# f28p551x_analog_subsys_regs register map
Vendor: Texas Instruments
Peripheral module from a debugger description file (folder C2000).
Address unit: 16 bits
Registers are 32-bit, read-write, no defined reset value unless marked. A register's access mark holds for its fields unless they carry their own. Offsets are as the file gives them; lines under a group give offsets from that group; [hi:lo] are bit positions; {n}, {i} and the like mark numbered series; 'fields as' and 'values as' point back to an identical list; <NAME> marks a mode.

## ANALOG_SUBSYS_REGS — ANALOG SUBSYS Registers
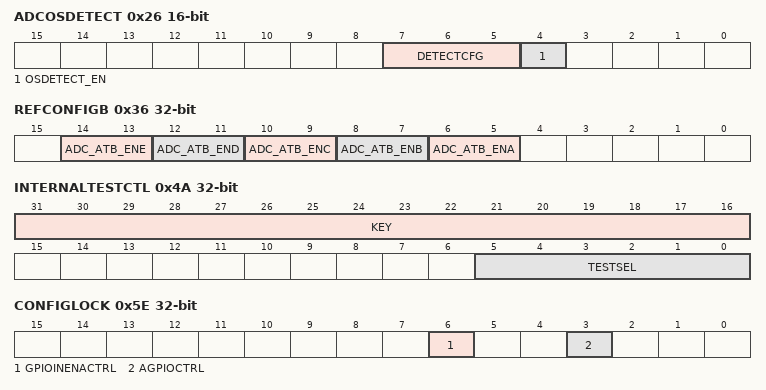
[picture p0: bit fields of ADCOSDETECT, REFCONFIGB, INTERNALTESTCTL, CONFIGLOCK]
0x26 ADCOSDETECT 16-bit — I2V Logic Control
  [7:5] DETECTCFG — OS detect config bits
  [4] OSDETECT_EN — Enable OS Detect Logic
0x36 REFCONFIGB — Config register for analog reference B.
  [14:13] ADC_ATB_ENE — ADC E testmux enable
  [12:11] ADC_ATB_END — ADC D testmux enable
  [10:9] ADC_ATB_ENC — ADC C testmux enable
  [8:7] ADC_ATB_ENB — ADC B testmux enable
  [6:5] ADC_ATB_ENA — ADC A testmux enable
0x4A INTERNALTESTCTL — INTERNALTEST Node Control Register
  [31:16] KEY — Key to Enable writes
  [5:0] TESTSEL — Test Select
0x5E CONFIGLOCK — Lock Register for all the config registers.
  [6] GPIOINENACTRL — Locks all GPIOINENACTRL Register
  [3] AGPIOCTRL — Locks all AGPIOCTRL Register
0x60 TSNSCTL 16-bit — Temperature Sensor Control Register
  [0] ENABLE — Temperature Sensor Enable
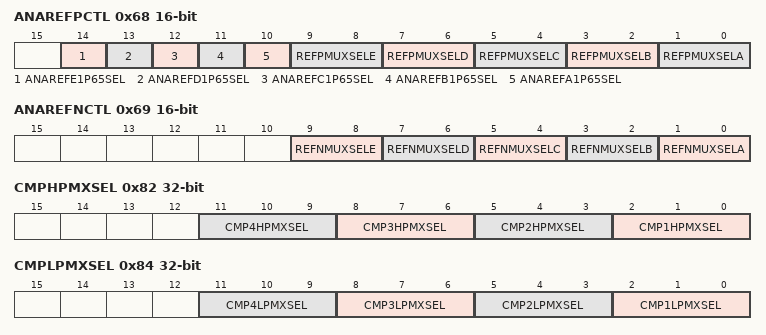
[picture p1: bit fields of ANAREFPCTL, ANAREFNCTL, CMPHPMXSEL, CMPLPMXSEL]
0x68 ANAREFPCTL 16-bit — Analog Reference Control Register for VREFHI
  [14] ANAREFE1P65SEL — 1.65v Reference Select ADCE
  [13] ANAREFD1P65SEL — 1.65v Reference Select ADCD
  [12] ANAREFC1P65SEL — 1.65v Reference Select ADCC
  [11] ANAREFB1P65SEL — 1.65v Reference Select ADCB
  [10] ANAREFA1P65SEL — 1.65v Reference Select ADCA
  [9:8] REFPMUXSELE — Analog Reference Select ADCE
  [7:6] REFPMUXSELD — Analog Reference Select ADCD
  [5:4] REFPMUXSELC — Analog Reference Select ADCC
  [3:2] REFPMUXSELB — Analog Reference Select ADCB
  [1:0] REFPMUXSELA — Analog Reference Select ADCA
0x69 ANAREFNCTL 16-bit — Analog Reference Control Register for VREFLO
  [9:8] REFNMUXSELE — Analog Reference Select ADCE
  [7:6] REFNMUXSELD — Analog Reference Select ADCD
  [5:4] REFNMUXSELC — Analog Reference Select ADCC
  [3:2] REFNMUXSELB — Analog Reference Select ADCB
  [1:0] REFNMUXSELA — Analog Reference Select ADCA
0x70 VMONCTL 16-bit — Voltage Monitor Control Register
  [8] BORLVMONDIS — Disable BORL(ow) feature on VDDIO
0x82 CMPHPMXSEL — Bits to select one of the many sources on CompHP inputs. Refer to Pimux diagram for details.
  [3n-1:3n-3] CMP{n}HPMXSEL (n=1..4) — CMP{n}HPMXSEL bits
0x84 CMPLPMXSEL — Bits to select one of the many sources on CompLP inputs. Refer to Pimux diagram for details.
  [3n-1:3n-3] CMP{n}LPMXSEL (n=1..4) — CMP{n}LPMXSEL bits
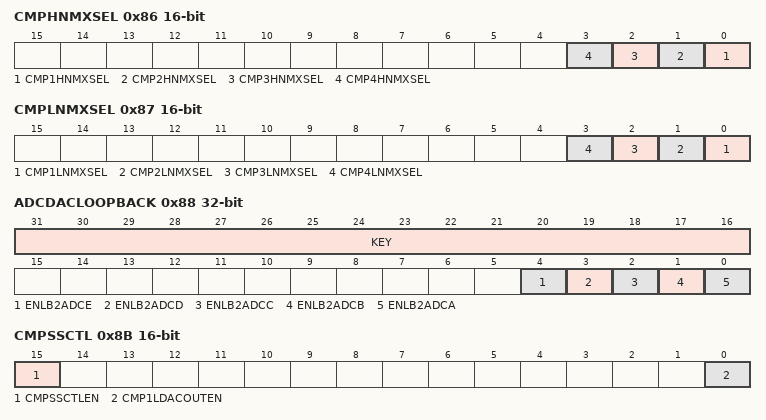
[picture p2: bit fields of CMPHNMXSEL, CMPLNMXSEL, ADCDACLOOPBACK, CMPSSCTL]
0x86 CMPHNMXSEL 16-bit — Bits to select one of the many sources on CompHN inputs. Refer to Pimux diagram for details.
  [n-1] CMP{n}HNMXSEL (n=1..4) — CMP{n}HNMXSEL bits
0x87 CMPLNMXSEL 16-bit — Bits to select one of the many sources on CompLN inputs. Refer to Pimux diagram for details.
  [n-1] CMP{n}LNMXSEL (n=1..4) — CMP{n}LNMXSEL bits
0x88 ADCDACLOOPBACK — Enabble loopback from DAC to ADCs
  [31:16] KEY — Key to enable writes
  [4] ENLB2ADCE — Enable DACA loopback to ADCE
  [3] ENLB2ADCD — Enable DACA loopback to ADCD
  [2] ENLB2ADCC — Enable DACA loopback to ADCC
  [1] ENLB2ADCB — Enable DACA loopback to ADCB
  [0] ENLB2ADCA — Enable DACA loopback to ADCA
0x8B CMPSSCTL 16-bit — CMPSS Control Register
  [15] CMPSSCTLEN — Enable the CMPSSCTL Register
  [0] CMP1LDACOUTEN — Enable general purpose DAC functionality for CMPSS1.COMPDACL
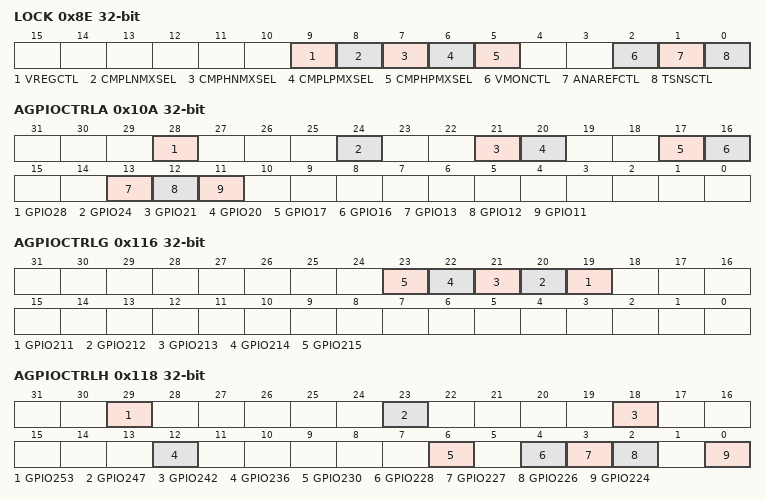
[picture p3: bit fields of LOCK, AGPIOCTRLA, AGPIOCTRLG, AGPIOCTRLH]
0x8E LOCK
  [9] VREGCTL — VREGCTL Register lock bit
  [8] CMPLNMXSEL — CMPLNMXSEL Register lock bit
  [7] CMPHNMXSEL — CMPHNMXSEL Register lock bit
  [6] CMPLPMXSEL — CMPLPMXSEL Register lock bit
  [5] CMPHPMXSEL — CMPHPMXSEL Register lock bit
  [2] VMONCTL — VMONCTL Register lock bit
  [1] ANAREFCTL — ANAREFCTL Register lock bit
  [0] TSNSCTL — TSNSCTL Register lock bit
0x10A AGPIOCTRLA — AGPIO Control Register
  [28] GPIO28 — AGPIOCTRL for GPIO28
  [24] GPIO24 — AGPIOCTRL for GPIO24
  [21] GPIO21 — AGPIOCTRL for GPIO21
  [20] GPIO20 — AGPIOCTRL for GPIO20
  [17] GPIO17 — AGPIOCTRL for GPIO17
  [16] GPIO16 — AGPIOCTRL for GPIO16
  [13] GPIO13 — AGPIOCTRL for GPIO13
  [12] GPIO12 — AGPIOCTRL for GPIO12
  [11] GPIO11 — AGPIOCTRL for GPIO11
0x10C AGPIOCTRLB — AGPIO Control Register
  [1] GPIO33 — AGPIOCTRL for GPIO33
0x116 AGPIOCTRLG — AGPIO Control Register
  [n-192] GPIO{n} (n=211..215) — AGPIOCTRL for GPIO{n}
0x118 AGPIOCTRLH — AGPIO Control Register
  [29] GPIO253 — AGPIOCTRL for GPIO253
  [23] GPIO247 — AGPIOCTRL for GPIO247
  [18] GPIO242 — AGPIOCTRL for GPIO242
  [12] GPIO236 — AGPIOCTRL for GPIO236
  [6] GPIO230 — AGPIOCTRL for GPIO230
  [4] GPIO228 — AGPIOCTRL for GPIO228
  [3] GPIO227 — AGPIOCTRL for GPIO227
  [2] GPIO226 — AGPIOCTRL for GPIO226
  [0] GPIO224 — AGPIOCTRL for GPIO224
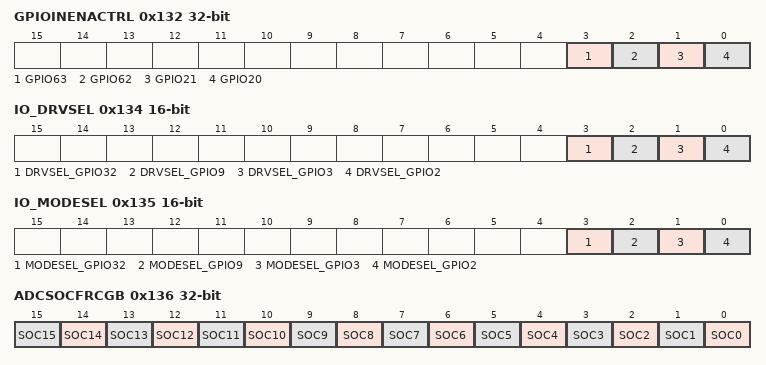
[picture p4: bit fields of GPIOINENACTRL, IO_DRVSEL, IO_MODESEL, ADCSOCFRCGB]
0x132 GPIOINENACTRL — GPIOINENACTRL Control Register
  [3] GPIO63 — Input Buffer Control for GPIO63
  [2] GPIO62 — Input Buffer Control for GPIO62
  [1] GPIO21 — Input Buffer Control for GPIO21
  [0] GPIO20 — Input Buffer Control for GPIO20
0x134 IO_DRVSEL 16-bit — IO Drive strength select register
  [3] DRVSEL_GPIO32 — Drive select for GPIO 32
  [2] DRVSEL_GPIO9 — Drive select for GPIO 9
  [1] DRVSEL_GPIO3 — Drive select for GPIO 3
  [0] DRVSEL_GPIO2 — Drive select for GPIO 2
0x135 IO_MODESEL 16-bit — IO Mode select register
  [3] MODESEL_GPIO32 — Mode select for GPIO 32
  [2] MODESEL_GPIO9 — Mode select for GPIO 9
  [1] MODESEL_GPIO3 — Mode select for GPIO 3
  [0] MODESEL_GPIO2 — Mode select for GPIO 2
0x136 ADCSOCFRCGB — ADC Global SOC Force
  [n] SOC{n} (n=0..15) — Generate synchronous SW trigger for SOC{n}
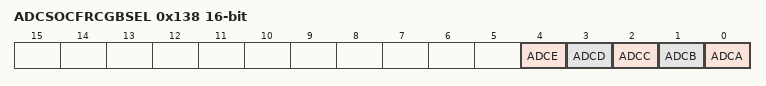
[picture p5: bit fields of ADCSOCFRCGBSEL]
0x138 ADCSOCFRCGBSEL 16-bit — ADC Global SOC Force Select
  [4] ADCE — Generate synchronous SW trigger for ADCE
  [3] ADCD — Generate synchronous SW trigger for ADCD
  [2] ADCC — Generate synchronous SW trigger for ADCC
  [1] ADCB — Generate synchronous SW trigger for ADCB
  [0] ADCA — Generate synchronous SW trigger for ADCA
